# VPAC0_PAR_VPAC_VISS0_S_VBUSP_VISS_FCP_FCC_VBUSP_FLEXCC_LINE register map
Vendor: Texas Instruments
Peripheral module from a debugger description file (folder J7ES).
Registers are 32-bit, access per field, reset 0x0 unless marked. A register's access mark holds for its fields unless they carry their own. Offsets are as the file gives them; lines under a group give offsets from that group; [hi:lo] are bit positions; {n}, {i} and the like mark numbered series; 'fields as' and 'values as' point back to an identical list; <NAME> marks a mode.

## VPAC0_PAR_VPAC_VISS0_S_VBUSP_VISS_FCP_FCC_VBUSP_FLEXCC_LINE
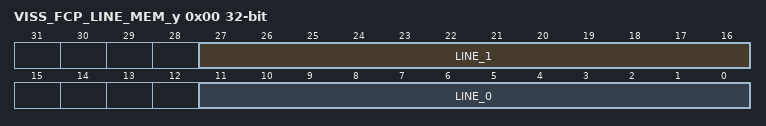
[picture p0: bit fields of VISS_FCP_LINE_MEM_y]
0x00 VISS_FCP_LINE_MEM_y — Memory for 2 lines of yuv444to420 Offset = 00098000h + (y * 4h); where y = 0h to FFFh
  [27:16] LINE_1 rw, [11:0] LINE_0 rw
